# npcx4m8f register map
Registers are 8-bit, read-write, no defined reset value unless marked. A register's access mark holds for its fields unless they carry their own. Offsets are from the block's base; [hi:lo] are bit positions; {n}, {i} and the like mark numbered series.

## PM2 — PM2 Module
Base 0x400CB000
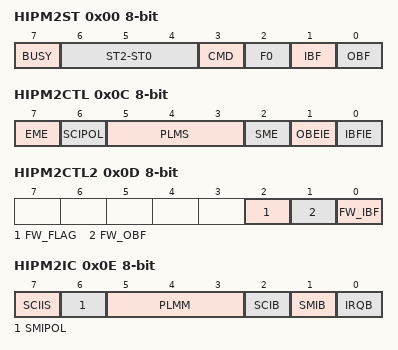
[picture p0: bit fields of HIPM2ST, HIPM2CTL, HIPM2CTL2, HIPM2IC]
0x00 HIPM2ST
  [7] BUSY, [6:4] ST2-ST0, [3] CMD, [2] F0, [1] IBF, [0] OBF
0x02 HIPM2DO
0x04 HIPM2DI
0x05 SHIPM2DI
0x06 HIPM2DOC
0x08 HIPM2DOM
0x0A HIPM2DIC
0x0C HIPM2CTL
  [7] EME, [6] SCIPOL, [5:3] PLMS, [2] SME, [1] OBEIE, [0] IBFIE
0x0D HIPM2CTL2
  [2] FW_FLAG, [1] FW_OBF, [0] FW_IBF
0x0E HIPM2IC
  [7] SCIIS, [6] SMIPOL, [5:3] PLMM, [2] SCIB, [1] SMIB, [0] IRQB
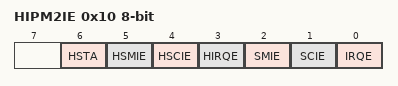
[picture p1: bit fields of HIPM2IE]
0x10 HIPM2IE
  [6] HSTA, [5] HSMIE, [4] HSCIE, [3] HIRQE, [2] SMIE, [1] SCIE, [0] IRQE
0x11 PM2_VER

## PM3 — PM3 Module
Base 0x400CD000
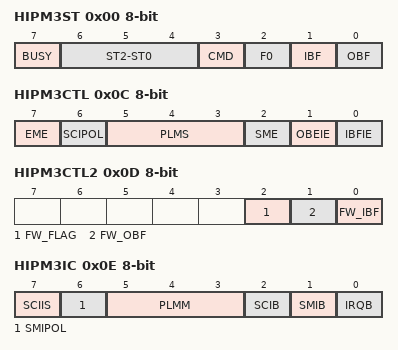
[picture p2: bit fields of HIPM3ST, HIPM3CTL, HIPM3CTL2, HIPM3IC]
0x00 HIPM3ST
  [7] BUSY, [6:4] ST2-ST0, [3] CMD, [2] F0, [1] IBF, [0] OBF
0x02 HIPM3DO
0x04 HIPM3DI
0x05 SHIPM3DI
0x06 HIPM3DOC
0x08 HIPM3DOM
0x0A HIPM3DIC
0x0C HIPM3CTL
  [7] EME, [6] SCIPOL, [5:3] PLMS, [2] SME, [1] OBEIE, [0] IBFIE
0x0D HIPM3CTL2
  [2] FW_FLAG, [1] FW_OBF, [0] FW_IBF
0x0E HIPM3IC
  [7] SCIIS, [6] SMIPOL, [5:3] PLMM, [2] SCIB, [1] SMIB, [0] IRQB
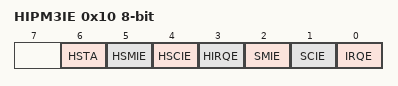
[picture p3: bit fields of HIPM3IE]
0x10 HIPM3IE
  [6] HSTA, [5] HSMIE, [4] HSCIE, [3] HIRQE, [2] SMIE, [1] SCIE, [0] IRQE
0x11 PM3_VER

## PM4 — PM4 Module
Base 0x400CF000
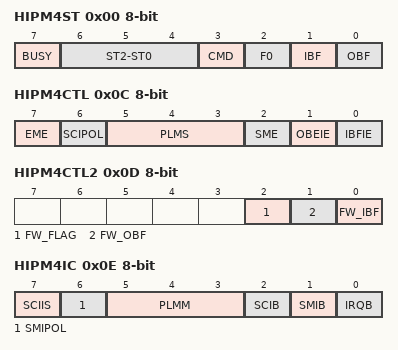
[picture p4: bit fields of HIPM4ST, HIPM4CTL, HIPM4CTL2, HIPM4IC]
0x00 HIPM4ST
  [7] BUSY, [6:4] ST2-ST0, [3] CMD, [2] F0, [1] IBF, [0] OBF
0x02 HIPM4DO
0x04 HIPM4DI
0x05 SHIPM4DI
0x06 HIPM4DOC
0x08 HIPM4DOM
0x0A HIPM4DIC
0x0C HIPM4CTL
  [7] EME, [6] SCIPOL, [5:3] PLMS, [2] SME, [1] OBEIE, [0] IBFIE
0x0D HIPM4CTL2
  [2] FW_FLAG, [1] FW_OBF, [0] FW_IBF
0x0E HIPM4IC
  [7] SCIIS, [6] SMIPOL, [5:3] PLMM, [2] SCIB, [1] SMIB, [0] IRQB
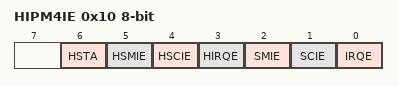
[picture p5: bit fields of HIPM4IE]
0x10 HIPM4IE
  [6] HSTA, [5] HSMIE, [4] HSCIE, [3] HIRQE, [2] SMIE, [1] SCIE, [0] IRQE
0x11 PM4_VER

## SHM — SHM Module
Base 0x40010000
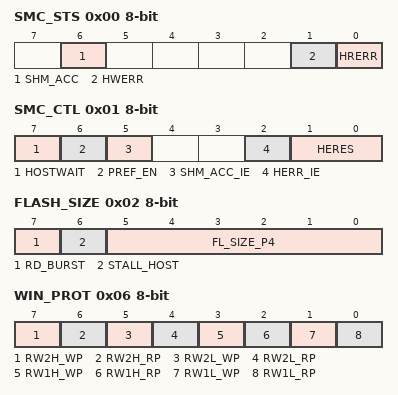
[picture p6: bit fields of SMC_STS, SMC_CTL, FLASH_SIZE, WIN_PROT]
0x00 SMC_STS
  [6] SHM_ACC, [1] HWERR, [0] HRERR
0x01 SMC_CTL
  [7] HOSTWAIT, [6] PREF_EN, [5] SHM_ACC_IE, [2] HERR_IE, [1:0] HERES
0x02 FLASH_SIZE
  [7] RD_BURST, [6] STALL_HOST, [5:0] FL_SIZE_P4
0x03 FWH_ID_LPC
  [3:0] BIOS_FWH_ID
0x04 WIN_BA_EXT1
0x05 WIN_BA_EXT2
0x06 WIN_PROT
  [7] RW2H_WP, [6] RW2H_RP, [5] RW2L_WP, [4] RW2L_RP, [3] RW1H_WP, [2] RW1H_RP, [1] RW1L_WP, [0] RW1L_RP
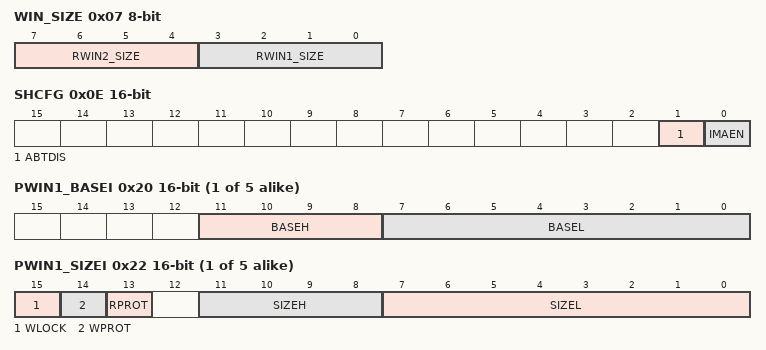
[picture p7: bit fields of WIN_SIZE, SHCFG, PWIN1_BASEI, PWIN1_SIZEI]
0x07 WIN_SIZE
  [7:4] RWIN2_SIZE, [3:0] RWIN1_SIZE
0x0A WIN_BASE1 16-bit
0x0C WIN_BASE2 16-bit
0x0E SHCFG 16-bit
  [1] ABTDIS, [0] IMAEN
{0x10+2i} SMCORP{i} 16-bit (i=0..3)
{0x18+2i} SMCOWP{i} 16-bit (i=0..3)
{0x1C+4i} PWIN{i}_BASEI 16-bit (i=1..5)
  [11:8] BASEH, [7:0] BASEL
{0x1E+4i} PWIN{i}_SIZEI 16-bit (i=1..5)
  [15] WLOCK, [14] WPROT, [13] RPROT, [11:8] SIZEH, [7:0] SIZEL
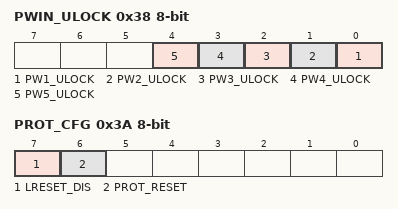
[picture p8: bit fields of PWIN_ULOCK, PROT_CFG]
0x38 PWIN_ULOCK
  [n-1] PW{n}_ULOCK (n=1..5)
0x39 ULOCK_OPEN
0x3A PROT_CFG
  [7] LRESET_DIS, [6] PROT_RESET
0x7F VERSION

## SCFG — SYSTEM CONFIGURATION
Base 0x400C3000
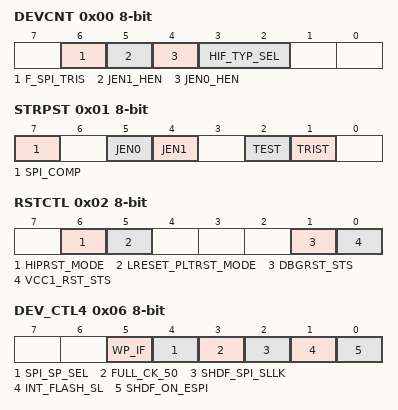
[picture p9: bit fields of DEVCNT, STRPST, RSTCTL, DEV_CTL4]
0x00 DEVCNT
  [6] F_SPI_TRIS, [5] JEN1_HEN, [4] JEN0_HEN, [3:2] HIF_TYP_SEL
0x01 STRPST
  [7] SPI_COMP, [5] JEN0, [4] JEN1, [2] TEST, [1] TRIST
0x02 RSTCTL
  [6] HIPRST_MODE, [5] LRESET_PLTRST_MODE, [1] DBGRST_STS, [0] VCC1_RST_STS
0x04 DEV_CTL3
  [1] RNGINT_MD
0x06 DEV_CTL4
  [5] WP_IF, [4] SPI_SP_SEL, [3] FULL_CK_50, [2] SHDF_SPI_SLLK, [1] INT_FLASH_SL, [0] SHDF_ON_ESPI
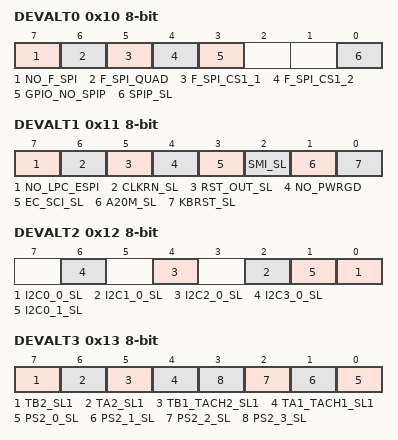
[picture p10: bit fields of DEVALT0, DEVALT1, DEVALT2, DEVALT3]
0x10 DEVALT0
  [7] NO_F_SPI, [6] F_SPI_QUAD, [5] F_SPI_CS1_1, [4] F_SPI_CS1_2, [3] GPIO_NO_SPIP, [0] SPIP_SL
0x11 DEVALT1
  [7] NO_LPC_ESPI, [6] CLKRN_SL, [5] RST_OUT_SL, [4] NO_PWRGD, [3] EC_SCI_SL, [2] SMI_SL, [1] A20M_SL, [0] KBRST_SL
0x12 DEVALT2
  [2n] I2C{n}_0_SL (n=0..3), [1] I2C0_1_SL
0x13 DEVALT3
  [7] TB2_SL1, [6] TA2_SL1, [5] TB1_TACH2_SL1, [4] TA1_TACH1_SL1, [n] PS2_{n}_SL (n=0..3)
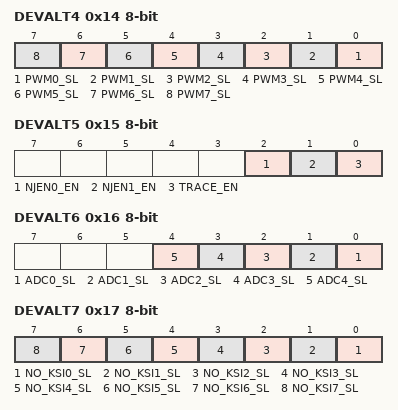
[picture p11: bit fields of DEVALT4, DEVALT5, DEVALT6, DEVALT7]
0x14 DEVALT4
  [n] PWM{n}_SL (n=0..7)
0x15 DEVALT5
  [2] NJEN0_EN, [1] NJEN1_EN, [0] TRACE_EN
0x16 DEVALT6
  [n] ADC{n}_SL (n=0..4)
0x17 DEVALT7
  [n] NO_KSI{n}_SL (n=0..7)
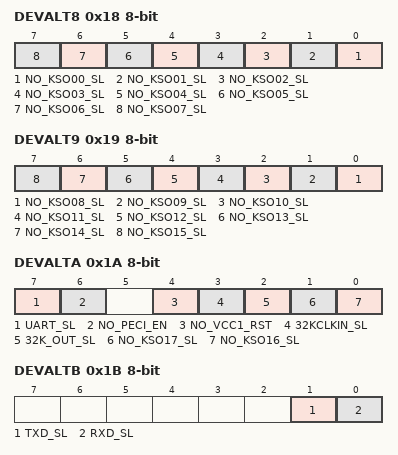
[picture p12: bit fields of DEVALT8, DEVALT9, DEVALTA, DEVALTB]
0x18 DEVALT8
  [n] NO_KSO{n:02}_SL (n=0..7)
0x19 DEVALT9
  [n-8] NO_KSO{n:02}_SL (n=8..15)
0x1A DEVALTA
  [7] UART_SL, [6] NO_PECI_EN, [4] NO_VCC1_RST, [3] 32KCLKIN_SL, [2] 32K_OUT_SL, [1] NO_KSO17_SL, [0] NO_KSO16_SL
0x1B DEVALTB
  [1] TXD_SL, [0] RXD_SL
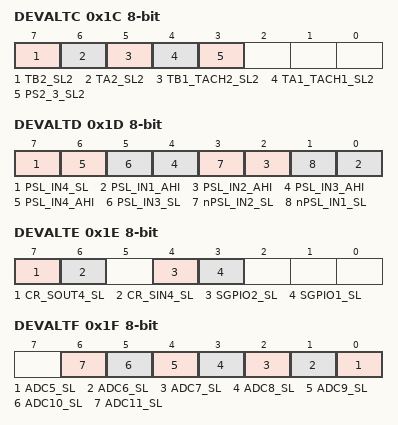
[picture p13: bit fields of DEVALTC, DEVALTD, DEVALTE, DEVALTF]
0x1C DEVALTC
  [7] TB2_SL2, [6] TA2_SL2, [5] TB1_TACH2_SL2, [4] TA1_TACH1_SL2, [3] PS2_3_SL2
0x1D DEVALTD
  [7] PSL_IN4_SL, [2n-2] PSL_IN{n}_AHI (n=1..4), [5] PSL_IN3_SL, [3] nPSL_IN2_SL, [1] nPSL_IN1_SL
0x1E DEVALTE
  [7] CR_SOUT4_SL, [6] CR_SIN4_SL, [4] SGPIO2_SL, [3] SGPIO1_SL
0x1F DEVALTF
  [n-5] ADC{n}_SL (n=5..11)
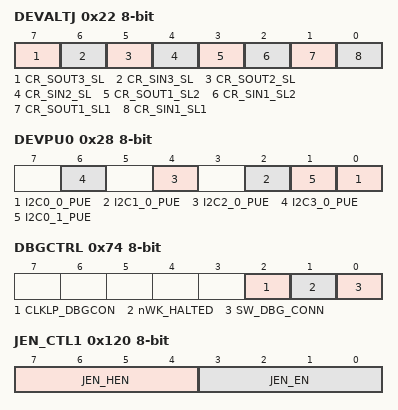
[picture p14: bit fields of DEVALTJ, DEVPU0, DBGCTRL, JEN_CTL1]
0x22 DEVALTJ
  [7] CR_SOUT3_SL, [6] CR_SIN3_SL, [5] CR_SOUT2_SL, [4] CR_SIN2_SL, [3] CR_SOUT1_SL2, [2] CR_SIN1_SL2, [1] CR_SOUT1_SL1, [0] CR_SIN1_SL1
0x28 DEVPU0
  [2n] I2C{n}_0_PUE (n=0..3), [1] I2C0_1_PUE
0x29 DEVPU1
  [7] F_SPI_PUD_EN
{0x2A+i} LV_GPIO_CTL{i} (i=0..3)
0x74 DBGCTRL
  [2] CLKLP_DBGCON, [1] nWK_HALTED, [0] SW_DBG_CONN
0x120 JEN_CTL1
  [7:4] JEN_HEN, [3:0] JEN_EN
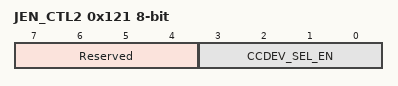
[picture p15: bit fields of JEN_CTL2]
0x121 JEN_CTL2
  [7:4] Reserved (must be 0h), [3:0] CCDEV_SEL_EN

## DBG — Debug Support
Base 0x400C3000
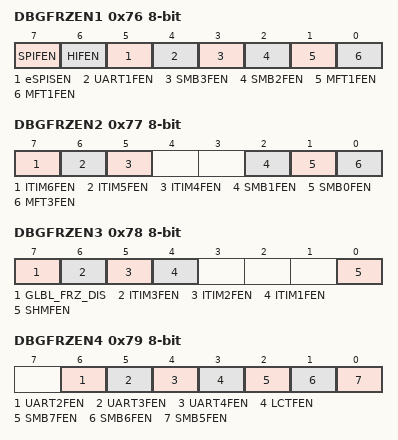
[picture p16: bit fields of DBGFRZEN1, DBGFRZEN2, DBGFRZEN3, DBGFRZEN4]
0x76 DBGFRZEN1
  [7] SPIFEN, [6] HIFEN, [5] eSPISEN, [4] UART1FEN, [3] SMB3FEN, [2] SMB2FEN, [1] MFT1FEN, [0] MFT1FEN
0x77 DBGFRZEN2
  [7] ITIM6FEN, [6] ITIM5FEN, [5] ITIM4FEN, [2] SMB1FEN, [1] SMB0FEN, [0] MFT3FEN
0x78 DBGFRZEN3
  [7] GLBL_FRZ_DIS, [6] ITIM3FEN, [5] ITIM2FEN, [4] ITIM1FEN, [0] SHMFEN
0x79 DBGFRZEN4
  [6] UART2FEN, [5] UART3FEN, [4] UART4FEN, [3] LCTFEN, [2] SMB7FEN, [1] SMB6FEN, [0] SMB5FEN

## SYSTEM_GLUE — System Glue Registers
Base 0x400A5000
0x10 SDPD0
0x12 SDPD1
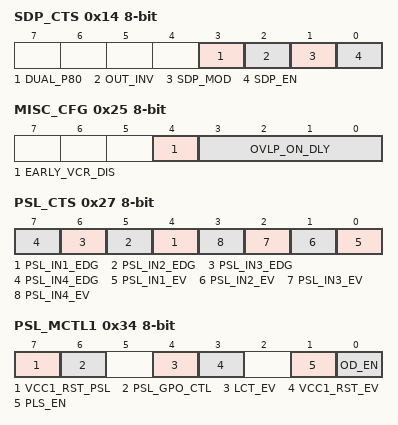
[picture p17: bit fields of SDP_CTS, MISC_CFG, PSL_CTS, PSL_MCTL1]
0x14 SDP_CTS
  [3] DUAL_P80, [2] OUT_INV, [1] SDP_MOD, [0] SDP_EN
0x1A GLUE_VER
0x21 SMB_SEL
  [0] SMB0_SL
0x25 MISC_CFG
  [4] EARLY_VCR_DIS, [3:0] OVLP_ON_DLY
0x27 PSL_CTS
  [n+3] PSL_IN{n}_EDG (n=1..4), [n-1] PSL_IN{n}_EV (n=1..4)
0x34 PSL_MCTL1
  [7] VCC1_RST_PSL, [6] PSL_GPO_CTL, [4] LCT_EV, [3] VCC1_RST_EV, [1] PLS_EN, [0] OD_EN
0x38 PSL_MCTL2
  [7] VCC1_RST_PSL_LK, [6] PSL_GP_EN, [3] AC_IN_BLOCK_EN, [1:0] AC_IN_SEL
0x40 SNT_STS
0x42 SNT_CTL
0x44 SNT_CFG

## MDC — Micellaneous Device Control Module
Base 0x4000C000
0x05 BSC0
0x07 BSC1
0x0A HEAD_BASEL 16-bit
0x0C HEAD_BASEH 16-bit
0x0E RAM_1T_CTL
  [5:1] CLK_1M_DIV, [0] STG_RFRSH
0x0F MDC_VERSION
0x10 RAM_1T_CLK_COUNT 16-bit
  [11:0] T_CLK_COUNT
0x11 RAM_1T_TCTL
  [7] T_COUNT_VALID, [6] T_SENS_DIS, [5] LOW_SMPL, [4] T_MEAS_WIN, [3] T_MEAS_DLY, [2:0] TFR_TRIM
0x12 RAM_WH_THR
0x13 RAM_CW_THR
0x14 RAM_1T_TMP1
  [5:3] COLD_DIV
0x15 RAM_1T_TMP2
  [5:3] HOT_DIV, [2:0] WARM_DIV
